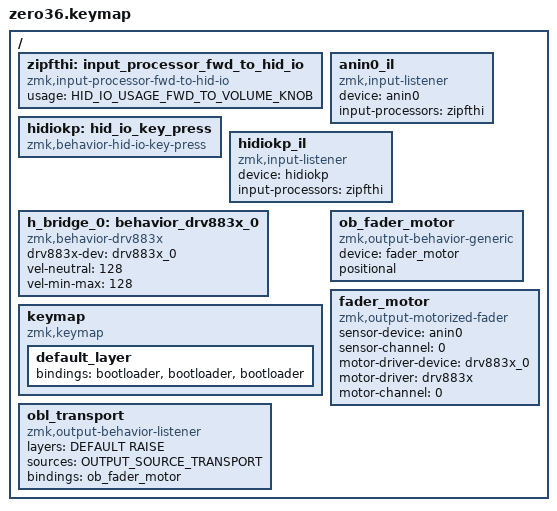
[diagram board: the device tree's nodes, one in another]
/*
 * Copyright (c) 2020 The ZMK Contributors
 *
 * SPDX-License-Identifier: MIT
 */

#include <zephyr/dt-bindings/input/input-event-codes.h>

#include <behaviors.dtsi>
#include <behaviors/mouse_keys.dtsi>
// #include <behaviors/mouse_key_press.dtsi>
// #include <behaviors/mouse_key_toggle.dtsi>
#include <dt-bindings/zmk/keys.h>
#include <dt-bindings/zmk/bt.h>
#include <dt-bindings/zmk/rgb.h>
#include <dt-bindings/zmk/ext_power.h>
#include <dt-bindings/zmk/outputs.h>
#include <dt-bindings/zmk/mouse.h>
#include <dt-bindings/zmk/input_transform.h>
#include <dt-bindings/zmk/rgb.h>

#define DEFAULT 0
#define RAISE   1

#define HID_IO_USAGE_FWD_TO_MOUSE 1
#define HID_IO_USAGE_FWD_TO_JOYSTICK 2
#define HID_IO_USAGE_FWD_TO_VOLUME_KNOB 3

/ {
        zipfthi: input_processor_fwd_to_hid_io {
                compatible = "zmk,input-processor-fwd-to-hid-io";
                #input-processor-cells = <0>;
                // usage = <HID_IO_USAGE_FWD_TO_JOYSTICK>;
                usage = <HID_IO_USAGE_FWD_TO_VOLUME_KNOB>;
        };

	anin0_il {
		compatible = "zmk,input-listener";
		device = <&anin0>;
                input-processors = <&zipfthi>;
	};

        hidiokp: hid_io_key_press {
                compatible = "zmk,behavior-hid-io-key-press";
                #binding-cells = <1>;
        };
	hidiokp_il {
		compatible = "zmk,input-listener";
		device = <&hidiokp>;
                input-processors = <&zipfthi>;
	};

        h_bridge_0: behavior_drv883x_0 {
                compatible = "zmk,behavior-drv883x";
                #binding-cells = <2>;
                drv883x-dev = <&drv883x_0>;
                vel-neutral = <128>;
                vel-min-max = <128>;
        };

        // h_bridge_0: behavior_tb6612fng {
        //         compatible = "zmk,behavior-tb6612fng";
        //         #binding-cells = <2>;
        //         tb6612fng-dev = <&tb6612fng_0>;
        //         vel-neutral = <128>;
        //         vel-min-max = <128>;
        // };

        keymap {
                compatible = "zmk,keymap";
                default_layer {
                        bindings = <

                                &bootloader        &bootloader      &bootloader

                                // &hidiokp 0      &hidiokp 1       &hidiokp 2
                                
                                // &h_bridge_0 0 160 // channel 0, speed +32 (forward)
                                // &h_bridge_0 0 128 // channel 0, speed 0   (neutral)
                                // &h_bridge_0 0 96  // channel 0, speed -32 (reverse)

                                // &h_bridge_0 0 192 // channel 0, speed +64 (forward)
                                // &h_bridge_0 0 128 // channel 0, speed 0   (neutral)
                                // &h_bridge_0 0 64  // channel 0, speed -64 (reverse)

                                // &h_bridge_0 0 224 // channel 0, speed +96 (forward)
                                // &h_bridge_0 0 128 // channel 0, speed 0   (neutral)
                                // &h_bridge_0 0 32  // channel 0, speed -96 (reverse)

                        >;
                };
                // raise_layer {
                //         bindings = <
                //                 &hidiokp 0      &hidiokp 1       &hidiokp 2
                //         >;
                // };
       };
};

#define OUTPUT_SOURCE_TRANSPORT 6
/{
        obl_transport {
                compatible = "zmk,output-behavior-listener";
                layers = <DEFAULT RAISE>;
                sources = <OUTPUT_SOURCE_TRANSPORT>;
                bindings = <&ob_fader_motor>;
        };
        ob_fader_motor: ob_fader_motor {
                compatible = "zmk,output-behavior-generic";
                #binding-cells = <0>;
                device = <&fader_motor>;
                positional;
        };
	fader_motor: fader_motor {
		compatible = "zmk,output-motorized-fader";
		#binding-cells = <0>;
                sensor-device = <&anin0>;
                sensor-channel = <0>;

                // motor-driver-device = <&tb6612fng_0>;
                // motor-driver = "tb6612fng";
                motor-driver-device = <&drv883x_0>;
                motor-driver = "drv883x";

                motor-channel = <0>;
	};

};
